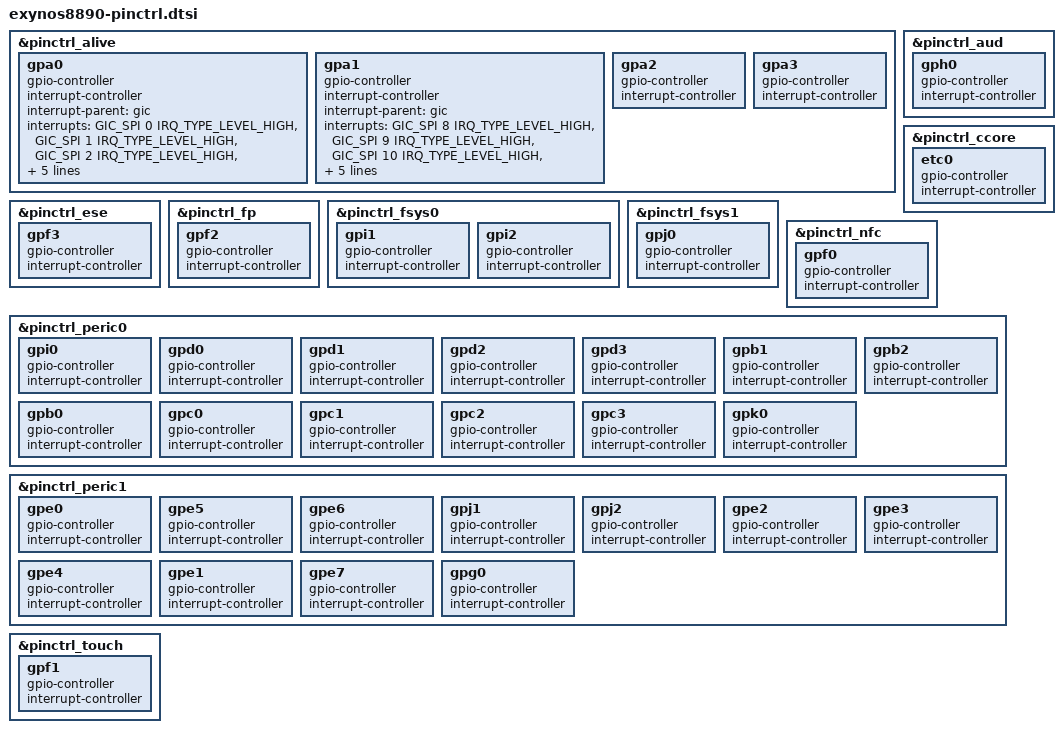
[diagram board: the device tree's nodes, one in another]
/*
 * Samsung's Exynos8890 SoC pin-mux and pin-config device tree source
 *
 * Copyright (c) 2013 Samsung Electronics Co., Ltd.
 *		http://www.samsung.com
 *
 * Samsung's Exynos8890 SoC pin-mux and pin-config options are listed as device
 * tree nodes are listed in this file.
 *
 * This program is free software; you can redistribute it and/or modify
 * it under the terms of the GNU General Public License version 2 as
 * published by the Free Software Foundation.
*/

&pinctrl_alive {
	gpa0: gpa0 {
		gpio-controller;
		#gpio-cells = <2>;

		interrupt-controller;
		interrupt-parent = <&gic>;
		interrupts = <GIC_SPI 0 IRQ_TYPE_LEVEL_HIGH>,
				<GIC_SPI 1 IRQ_TYPE_LEVEL_HIGH>,
				<GIC_SPI 2 IRQ_TYPE_LEVEL_HIGH>,
				<GIC_SPI 3 IRQ_TYPE_LEVEL_HIGH>,
				<GIC_SPI 4 IRQ_TYPE_LEVEL_HIGH>,
				<GIC_SPI 5 IRQ_TYPE_LEVEL_HIGH>,
				<GIC_SPI 6 IRQ_TYPE_LEVEL_HIGH>,
				<GIC_SPI 7 IRQ_TYPE_LEVEL_HIGH>;
		#interrupt-cells = <2>;
	};

	gpa1: gpa1 {
		gpio-controller;
		#gpio-cells = <2>;

		interrupt-controller;
		interrupt-parent = <&gic>;
		interrupts = <GIC_SPI 8 IRQ_TYPE_LEVEL_HIGH>,
				<GIC_SPI 9 IRQ_TYPE_LEVEL_HIGH>,
				<GIC_SPI 10 IRQ_TYPE_LEVEL_HIGH>,
				<GIC_SPI 11 IRQ_TYPE_LEVEL_HIGH>,
				<GIC_SPI 12 IRQ_TYPE_LEVEL_HIGH>,
				<GIC_SPI 13 IRQ_TYPE_LEVEL_HIGH>,
				<GIC_SPI 14 IRQ_TYPE_LEVEL_HIGH>,
				<GIC_SPI 15 IRQ_TYPE_LEVEL_HIGH>;
		#interrupt-cells = <IRQ_TYPE_LEVEL_HIGH>;
	};

	gpa2: gpa2 {
		gpio-controller;
		#gpio-cells = <2>;

		interrupt-controller;
		#interrupt-cells = <2>;
	};

	gpa3: gpa3 {
		gpio-controller;
		#gpio-cells = <2>;

		interrupt-controller;
		#interrupt-cells = <2>;
	};
};

&pinctrl_aud {
	gph0: gph0 {
		gpio-controller;
		#gpio-cells = <2>;

		interrupt-controller;
		#interrupt-cells = <2>;
	};
};

&pinctrl_ccore {
	etc0: etc0 {
		gpio-controller;
		#gpio-cells = <2>;

		interrupt-controller;
		#interrupt-cells = <2>;
	};
};

&pinctrl_ese {
	gpf3: gpf3 {
		gpio-controller;
		#gpio-cells = <2>;

		interrupt-controller;
		#interrupt-cells = <2>;
	};
};

&pinctrl_fp {
	gpf2: gpf2 {
		gpio-controller;
		#gpio-cells = <2>;

		interrupt-controller;
		#interrupt-cells = <2>;
	};
};

&pinctrl_fsys0 {
	gpi1: gpi1 {
		gpio-controller;
		#gpio-cells = <2>;

		interrupt-controller;
		#interrupt-cells = <2>;
	};

	gpi2: gpi2 {
		gpio-controller;
		#gpio-cells = <2>;

		interrupt-controller;
		#interrupt-cells = <2>;
	};
};

&pinctrl_fsys1 {
	gpj0: gpj0 {
		gpio-controller;
		#gpio-cells = <2>;

		interrupt-controller;
		#interrupt-cells = <2>;
	};
};

&pinctrl_nfc {
	gpf0: gpf0 {
		gpio-controller;
		#gpio-cells = <2>;

		interrupt-controller;
		#interrupt-cells = <2>;
	};
};

&pinctrl_peric0 {
	gpi0: gpi0 {
		gpio-controller;
		#gpio-cells = <2>;

		interrupt-controller;
		#interrupt-cells = <2>;
	};

	gpd0: gpd0 {
		gpio-controller;
		#gpio-cells = <2>;

		interrupt-controller;
		#interrupt-cells = <2>;
	};

	gpd1: gpd1 {
		gpio-controller;
		#gpio-cells = <2>;

		interrupt-controller;
		#interrupt-cells = <2>;
	};

	gpd2: gpd2 {
		gpio-controller;
		#gpio-cells = <2>;

		interrupt-controller;
		#interrupt-cells = <2>;
	};

	gpd3: gpd3 {
		gpio-controller;
		#gpio-cells = <2>;

		interrupt-controller;
		#interrupt-cells = <2>;
	};

	gpb1: gpb1 {
		gpio-controller;
		#gpio-cells = <2>;

		interrupt-controller;
		#interrupt-cells = <2>;
	};

	gpb2: gpb2 {
		gpio-controller;
		#gpio-cells = <2>;

		interrupt-controller;
		#interrupt-cells = <2>;
	};

	gpb0: gpb0 {
		gpio-controller;
		#gpio-cells = <2>;

		interrupt-controller;
		#interrupt-cells = <2>;
	};

	gpc0: gpc0 {
		gpio-controller;
		#gpio-cells = <2>;

		interrupt-controller;
		#interrupt-cells = <2>;
	};

	gpc1: gpc1 {
		gpio-controller;
		#gpio-cells = <2>;

		interrupt-controller;
		#interrupt-cells = <2>;
	};

	gpc2: gpc2 {
		gpio-controller;
		#gpio-cells = <2>;

		interrupt-controller;
		#interrupt-cells = <2>;
	};

	gpc3: gpc3 {
		gpio-controller;
		#gpio-cells = <2>;

		interrupt-controller;
		#interrupt-cells = <2>;
	};

	gpk0: gpk0 {
		gpio-controller;
		#gpio-cells = <2>;

		interrupt-controller;
		#interrupt-cells = <2>;
	};
};

&pinctrl_peric1 {
	gpe0: gpe0 {
		gpio-controller;
		#gpio-cells = <2>;

		interrupt-controller;
		#interrupt-cells = <2>;
	};

	gpe5: gpe5 {
		gpio-controller;
		#gpio-cells = <2>;

		interrupt-controller;
		#interrupt-cells = <2>;
	};

	gpe6: gpe6 {
		gpio-controller;
		#gpio-cells = <2>;

		interrupt-controller;
		#interrupt-cells = <2>;
	};

	gpj1: gpj1 {
		gpio-controller;
		#gpio-cells = <2>;

		interrupt-controller;
		#interrupt-cells = <2>;
	};

	gpj2: gpj2 {
		gpio-controller;
		#gpio-cells = <2>;

		interrupt-controller;
		#interrupt-cells = <2>;
	};

	gpe2: gpe2 {
		gpio-controller;
		#gpio-cells = <2>;

		interrupt-controller;
		#interrupt-cells = <2>;
	};

	gpe3: gpe3 {
		gpio-controller;
		#gpio-cells = <2>;

		interrupt-controller;
		#interrupt-cells = <2>;
	};

	gpe4: gpe4 {
		gpio-controller;
		#gpio-cells = <2>;

		interrupt-controller;
		#interrupt-cells = <2>;
	};

	gpe1: gpe1 {
		gpio-controller;
		#gpio-cells = <2>;

		interrupt-controller;
		#interrupt-cells = <2>;
	};

	gpe7: gpe7 {
		gpio-controller;
		#gpio-cells = <2>;

		interrupt-controller;
		#interrupt-cells = <2>;
	};

	gpg0: gpg0 {
		gpio-controller;
		#gpio-cells = <2>;

		interrupt-controller;
		#interrupt-cells = <2>;
	};
};

&pinctrl_touch {
	gpf1: gpf1 {
		gpio-controller;
		#gpio-cells = <2>;

		interrupt-controller;
		#interrupt-cells = <2>;
	};
};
